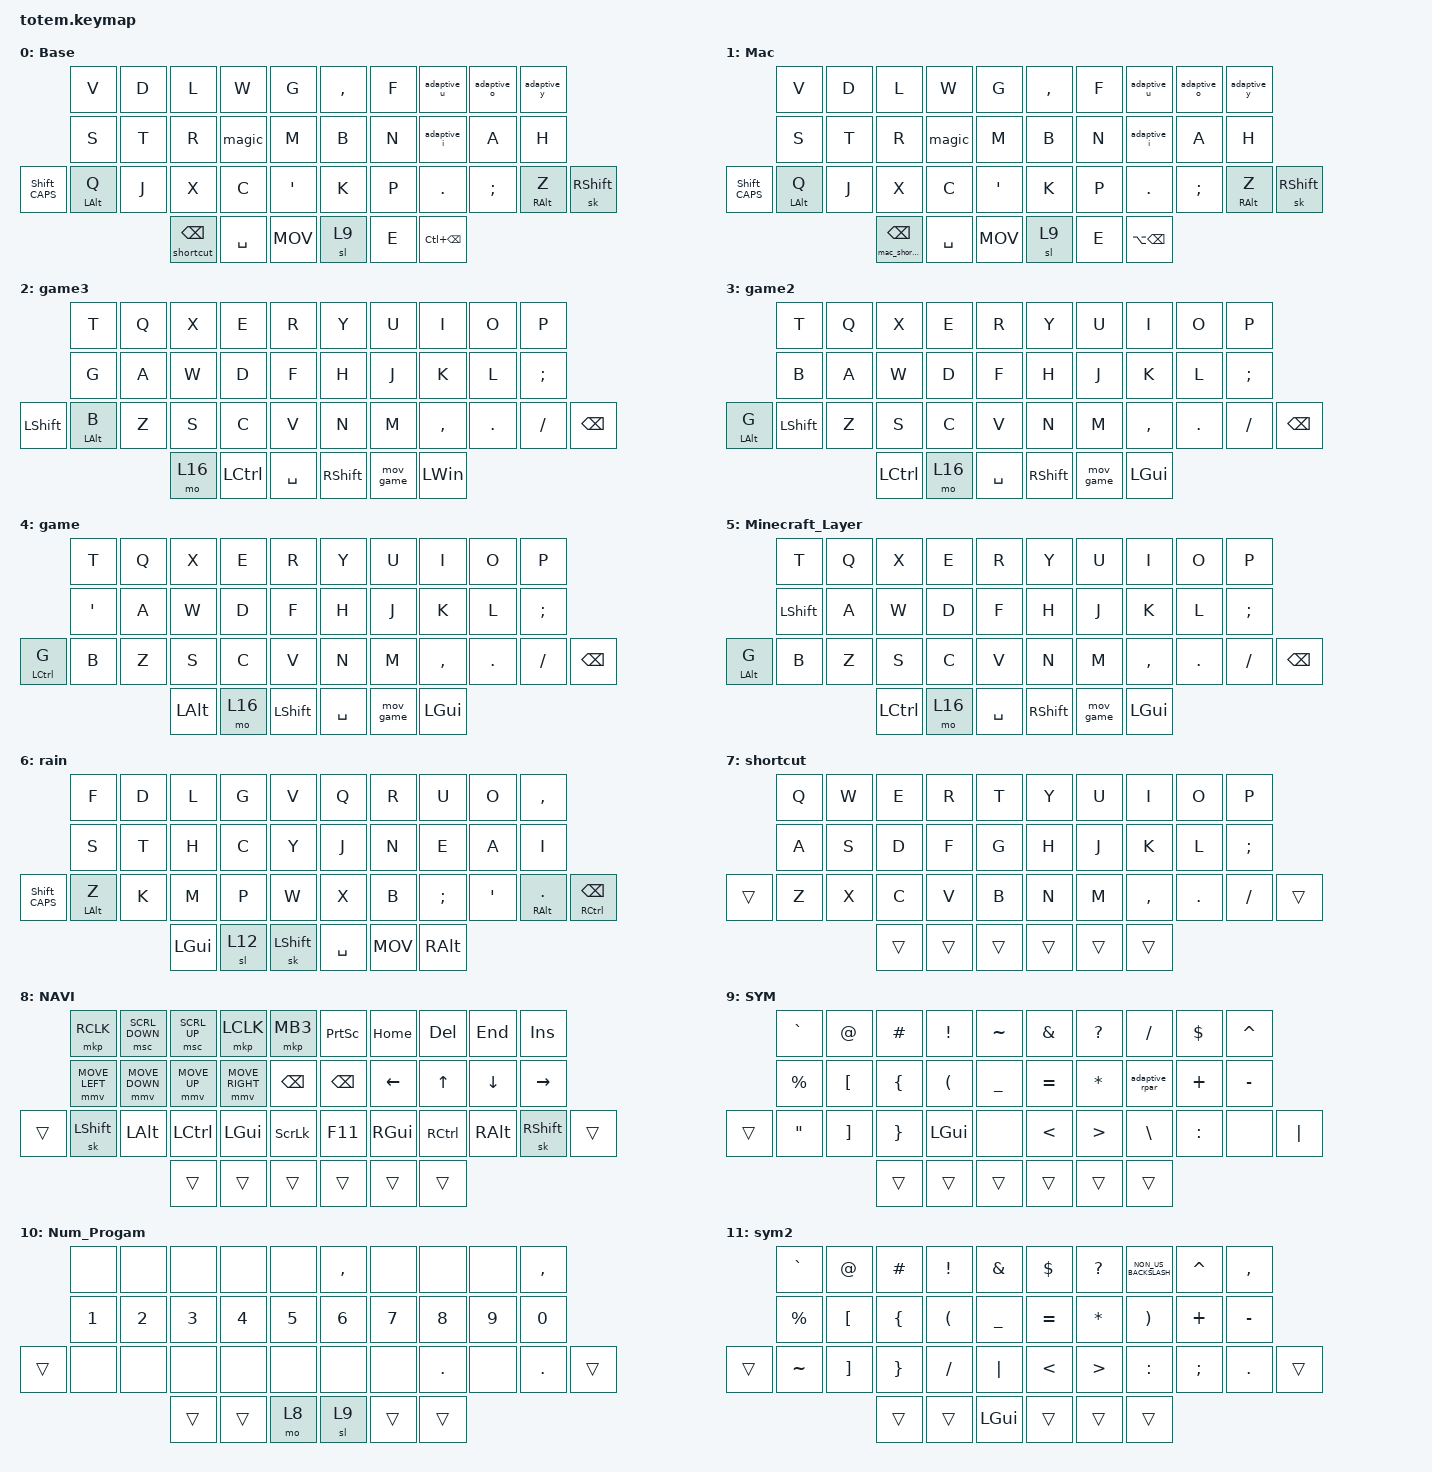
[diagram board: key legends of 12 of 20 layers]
//
//                                                        ▀▀▀▀▀     ▀▀▀▀▀          ▀▀█▀▀
//                                                        ▄▀▀▀▄  ▄  ▄▀▀▀▄  ▄  ▄▀▀▀▄  █  ▄▀▀▀▄
//                                                        █   █  █  █   █  █  █   █  █  █   █
//                                                         ▀▀▀   █   ▀▀▀   █   ▀▀▀   ▀   ▀▀▀
//                                                               █     ▄▄▄█▄▄▄    █   █  
//                                                               ▀     █  █  █     █▄█
//                                                             ▀▀▀▀▀    █  █  █      ▀
//                                                                      ▀  ▀  ▀
//
// ▄▄▄▄▄▄▄▄▄▄▄▄▄▄▄▄▄▄▄▄▄▄▄▄▄▄▄▄▄▄▄▄▄▄▄▄▄▄▄▄▄▄▄▄▄▄▄▄▄▄▄▄▄▄▄▄▄▄▄▄▄▄▄▄▄▄▄▄▄▄▄▄▄▄▄▄▄▄▄▄▄▄▄▄▄▄▄▄▄▄▄▄▄▄▄▄▄▄▄▄▄▄▄▄▄▄▄▄▄▄▄▄▄▄▄▄▄▄▄▄▄▄▄▄▄▄▄▄▄▄▄▄▄▄▄▄▄▄▄▄▄▄▄▄▄▄▄▄▄

#include <behaviors/mouse_keys.dtsi>
#include <dt-bindings/zmk/mouse.h>
#include <behaviors/battery_percentage_printer.dtsi>
#include <behaviors.dtsi>
#include <dt-bindings/zmk/bt.h>
#include <dt-bindings/zmk/keys.h>
#include <dt-bindings/zmk/outputs.h>
#include <dt-bindings/zmk/pointing.h>

#define ZMK_POINTING_DEFAULT_MOVE_VAL 4000 // default: 600
#define ZMK_POINTING_DEFAULT_SCRL_VAL 15    // default: 10
#define BASE 0
#define NAV  1
#define SYM  2
#define ADJ  3

&mt {
    quick-tap-ms = <100>;
    global-quick-tap;
    flavor = "tap-preferred";
    tapping-term-ms = <250>;
};

&sk {
    quick-release;
    release-after-ms = <1500>;
};

&soft_off {
    hold-time-ms = <2000>; // Only turn off it the key is held for 3 seconds or longer.
};

&sl { release-after-ms = <350>; };

/ {
    combos {
        compatible = "zmk,combos";

        esc {
            timeout-ms = <30>;
            key-positions = <2 1>;
            bindings = <&kp ESC>;
            layers = <2 13 8 0 13 3 4 6 1 5>;
        };

        enter {
            bindings = <&kp ENTER>;
            key-positions = <16 17 18>;
            timeout-ms = <30>;
            layers = <2 13 8 0 13 3 4 6 1 5>;
        };

        tab {
            bindings = <&kp TAB>;
            key-positions = <13 12>;
            timeout-ms = <30>;
            layers = <13 8 0 13 6 1>;
        };

        option {
            bindings = <&mo 14>;
            key-positions = <22 23 21>;
            timeout-ms = <30>;
            layers = <2 0 13 3 4 6 1 5>;
        };

        Bluetooth {
            bindings = <&mo 15>;
            key-positions = <2 3 1>;
            timeout-ms = <100>;
            layers = <2 0 3 4 6 1 5>;
        };

        Option_2 {
            bindings = <&mo 14>;
            key-positions = <29 28 30>;
            timeout-ms = <30>;
            layers = <2 0 3 4 6 1 5>;
        };

        Reset_Button {
            bindings = <&kp LC(RA(K))>;
            key-positions = <20 31 35 34>;
            timeout-ms = <50>;
            layers = <2 0 3 4 6 1>;
        };

        tabgaming {
            bindings = <&kp TAB>;
            key-positions = <3 2>;
            timeout-ms = <30>;
            layers = <2 4 3 5>;
        };
    };

    macros {
        macro_ou: macro_ou {
            compatible = "zmk,behavior-macro";
            #binding-cells = <0>;
            wait-ms = <20>;
            tap-ms = <20>;
            bindings = <&kp O &kp U>;
        };

        shortcut: shortcut {
            compatible = "zmk,behavior-macro";
            #binding-cells = <0>;
            bindings =
                <&macro_press>,
                <&kp LCTRL &mo 7>,
                <&macro_pause_for_release>,
                <&macro_release>,
                <&mo 7 &kp LCTRL>;

            label = "SHORTCUT";
        };

        macro_ng: macro_ng {
            compatible = "zmk,behavior-macro";
            #binding-cells = <0>;
            bindings = <&none>;
            label = "MACRO_NG";
        };

        mac_shortcut: mac_shortcut {
            compatible = "zmk,behavior-macro";
            #binding-cells = <0>;
            bindings =
                <&macro_press>,
                <&kp LEFT_ALT &mo 7>,
                <&macro_pause_for_release>,
                <&macro_release>,
                <&mo 7 &kp LEFT_ALT>;

            label = "MAC_SHORTCUT";
        };
    };

    behaviors {
        Shift_CAPS: Shift_CAPS {
            compatible = "zmk,behavior-tap-dance";
            label = "SHIFT_CAPS";
            #binding-cells = <0>;
            bindings = <&sk LEFT_SHIFT>, <&kp CAPSLOCK>;

            tapping-term-ms = <250>;
        };

        Pressy_Layer: Pressy_Layer {
            compatible = "zmk,behavior-tap-dance";
            label = "PRESSY_LAYER";
            #binding-cells = <0>;
            bindings = <&none>, <&none>, <&tog 19>;

            tapping-term-ms = <250>;
        };

        SYM_NUM: SYM_NUM {
            compatible = "zmk,behavior-tap-dance";
            label = "SYM_NUM";
            #binding-cells = <0>;
            bindings = <&sl 7>, <&sl 13>;

            tapping-term-ms = <250>;
        };

        MOV: MOV {
            compatible = "zmk,behavior-tap-dance";
            label = "MOV";
            #binding-cells = <0>;
            bindings = <&mo 8>, <&tog 8>;

            tapping-term-ms = <300>;
        };

        Backspace1: Backspace1 {
            compatible = "zmk,behavior-tap-dance";
            label = "BACKSPACE1";
            #binding-cells = <0>;
            bindings = <&kp BACKSPACE>;
            tapping-term-ms = <450>;
        };

        mov_game: mov_game {
            compatible = "zmk,behavior-tap-dance";
            label = "MOV_GAME";
            #binding-cells = <0>;
            bindings = <&mo 7>, <&mo 8>;

            tapping-term-ms = <300>;
        };

        Backspace_N_Ctrl: Backspace_N_Ctrl {
            compatible = "zmk,behavior-hold-tap";
            label = "BACKSPACE_N_CTRL";
            bindings = <&kp>, <&kp>;

            #binding-cells = <2>;
            tapping-term-ms = <400>;
            flavor = "tap-preferred";
        };

        Left_ALT: Left_ALT {
            compatible = "zmk,behavior-hold-tap";
            label = "LEFT_ALT";
            bindings = <&kp>, <&kp>;

            #binding-cells = <2>;
            flavor = "tap-preferred";
            tapping-term-ms = <400>;
        };

        Right_ALT: Right_ALT {
            compatible = "zmk,behavior-hold-tap";
            label = "RIGHT_ALT";
            bindings = <&kp>, <&kp>;

            #binding-cells = <2>;
            tapping-term-ms = <500>;
            flavor = "tap-preferred";
        };

        new_behavior: new_behavior {
            compatible = "zmk,behavior-hold-tap";
            label = "NEW_BEHAVIOR";
            bindings = <&kp>, <&kp>;

            #binding-cells = <2>;
            flavor = "tap-preferred";
            tapping-term-ms = <500>;
        };

        adaptive_o: adaptive_o {
            compatible = "zmk,behavior-adaptive-key";
            #binding-cells = <0>;

            /* Default output is O */

            bindings = <&kp O>;

            /* If U was pressed right before this, output I instead */

            akt_u {
                trigger-keys = <U>;
                max-prior-idle-ms = <1000>;
                bindings = <&kp I>;
            };
        };

        adaptive_i: adaptive_i {
            compatible = "zmk,behavior-adaptive-key";
            #binding-cells = <0>;

            /* Default output is I */

            bindings = <&kp I>;

            /* If U was pressed right before this, output O instead */

            akt_u {
                trigger-keys = <U>;
                max-prior-idle-ms = <1000>;
                bindings = <&kp O>;
            };
        };

        adaptive_y: adaptive_y {
            compatible = "zmk,behavior-adaptive-key";
            #binding-cells = <0>;

            /* Default output is Y */

            bindings = <&kp Y>;

            /* If E was pressed right before this, output U instead */

            akt_e {
                trigger-keys = <E>;
                max-prior-idle-ms = <1000>;
                bindings = <&kp U>;
            };
        };

        adaptive_u: adaptive_u {
            compatible = "zmk,behavior-adaptive-key";
            #binding-cells = <0>;

            /* Default output is U */

            bindings = <&kp U>;

            /* If E was pressed right before this, output Y instead */

            akt_e {
                trigger-keys = <E>;
                max-prior-idle-ms = <1000>;
                bindings = <&kp Y>;
            };
        };

        adaptive_rpar: adaptive_rpar {
            compatible = "zmk,behavior-adaptive-key";
            #binding-cells = <0>;

            /* Output default adalah ')' */

            bindings = <&kp RPAR>;

            /* Kalau sebelum tombol ini dipencet '>' (GT), ubah output ')' jadi '=' (hasil akhir: '>=') */

            akt_gt {
                trigger-keys = <GT>;
                max-prior-idle-ms = <1000>;
                bindings = <&kp EQUAL>;
            };

            /* Kalau sebelum tombol ini dipencet '<' (LT), ubah output ')' jadi '=' (hasil akhir: '<=') */

            akt_lt {
                trigger-keys = <LT>;
                max-prior-idle-ms = <1000>;
                bindings = <&kp EQUAL>;
            };

            /* Kalau sebelum tombol ini dipencet '=' (EQUAL), ubah output ')' jadi '>' (hasil akhir: '=>') */

            akt_eq {
                trigger-keys = <EQUAL>;
                max-prior-idle-ms = <1000>;
                bindings = <&kp GREATER_THAN>;
            };
        };

        magic: magic_key {
            compatible = "zmk,behavior-adaptive-key";
            #binding-cells = <0>;
            bindings = <&key_repeat>;

            /* Default output if no trigger matches (Repeat Key) */

            akt_bu {
                trigger-keys = <B>;
                max-prior-idle-ms = <1000>;
                bindings = <&kp U>;
            };

            akt_hy {
                trigger-keys = <H>;
                max-prior-idle-ms = <1000>;
                bindings = <&kp Y>;
            };

            akt_rl {
                trigger-keys = <R>;
                max-prior-idle-ms = <1000>;
                bindings = <&kp L>;
            };

            akt_yDOT {
                trigger-keys = <Y>;
                max-prior-idle-ms = <1000>;
                bindings = <&kp DOT>;
            };

            akt_ay {
                trigger-keys = <A>;
                max-prior-idle-ms = <1000>;
                bindings = <&kp Y>;
            };

            akt_kn {
                trigger-keys = <K>;
                max-prior-idle-ms = <1000>;
                bindings = <&kp N>;
            };

            akt_nk {
                trigger-keys = <N>;
                max-prior-idle-ms = <1000>;
                bindings = <&kp K>;
            };
        };

        Backspace_Shortuct: Backspace_Shortuct {
            compatible = "zmk,behavior-hold-tap";
            label = "BACKSPACE_SHORTUCT";
            bindings = <&shortcut>, <&kp>;

            #binding-cells = <2>;
            tapping-term-ms = <400>;
            quick-tap-ms = <175>;
            require-prior-idle-ms = <125>;
            flavor = "balanced";
            retro-tap;
        };

        SL6_Windows: SL6_Windows {
            compatible = "zmk,behavior-tap-dance";
            label = "SL6_WINDOWS";
            #binding-cells = <0>;
            bindings = <&sl 7>, <&kp LGUI>;

            tapping-term-ms = <150>;
        };

        MAC_Backspace_Shortcut: MAC_Backspace_Shortcut {
            compatible = "zmk,behavior-hold-tap";
            label = "MAC_BACKSPACE_SHORTCUT";
            bindings = <&mac_shortcut>, <&kp>;

            #binding-cells = <2>;
            flavor = "balanced";
            tapping-term-ms = <400>;
            quick-tap-ms = <175>;
            require-prior-idle-ms = <125>;
            retro-tap;
        };
    };

    keymap {
        compatible = "zmk,keymap";

        // ▄▄▄▄▄▄▄▄▄▄▄▄▄▄▄▄▄▄▄▄▄▄▄▄▄▄▄▄▄▄▄▄▄▄▄▄▄▄▄▄▄▄▄▄▄▄▄▄▄▄▄▄▄▄▄▄▄▄▄▄▄▄▄▄▄▄▄▄▄▄▄▄▄▄▄▄▄▄▄▄▄▄▄▄▄▄▄▄▄▄▄▄▄▄▄▄▄▄▄▄▄▄▄▄▄▄▄▄▄▄▄▄▄▄▄▄▄▄▄▄▄▄▄▄▄▄▄▄▄▄▄▄▄▄▄▄▄▄▄▄▄▄▄▄▄▄▄▄▄

        sunstone_code {
            label = "Base";
            bindings = <
             &kp V                 &kp D  &kp L                            &kp W      &kp G      &kp COMMA  &kp F  &adaptive_u        &adaptive_o  &adaptive_y
             &kp S                 &kp T  &kp R                            &magic     &kp M      &kp B      &kp N  &adaptive_i        &kp A        &kp H
&Shift_CAPS  &Left_ALT LEFT_ALT Q  &kp J  &kp X                            &kp C      &kp SQT    &kp K      &kp P  &kp DOT            &kp SEMI     &Right_ALT RIGHT_ALT Z  &sk RIGHT_SHIFT
                                          &Backspace_Shortuct 0 BACKSPACE  &kp SPACE  &MOV       &sl 9      &kp E  &kp LC(BACKSPACE)
            >;
        };

        BaseMac {
            label = "Mac";
            bindings = <
             &kp V                 &kp D  &kp L                                &kp W      &kp G      &kp COMMA  &kp F  &adaptive_u        &adaptive_o  &adaptive_y
             &kp S                 &kp T  &kp R                                &magic     &kp M      &kp B      &kp N  &adaptive_i        &kp A        &kp H
&Shift_CAPS  &Left_ALT LEFT_ALT Q  &kp J  &kp X                                &kp C      &kp SQT    &kp K      &kp P  &kp DOT            &kp SEMI     &Right_ALT RIGHT_ALT Z  &sk RIGHT_SHIFT
                                          &MAC_Backspace_Shortcut 0 BACKSPACE  &kp SPACE  &MOV       &sl 9      &kp E  &kp LA(BACKSPACE)
            >;
        };

        Gaming_Volley {
            label = "game3";
            bindings = <
                &kp T           &kp Q  &kp X   &kp E             &kp R        &kp Y            &kp U      &kp I         &kp O    &kp P
                &kp G           &kp A  &kp W   &kp D             &kp F        &kp H            &kp J      &kp K         &kp L    &kp SEMI
&kp LEFT_SHIFT  &mt LEFT_ALT B  &kp Z  &kp S   &kp C             &kp V        &kp N            &kp M      &kp COMMA     &kp DOT  &kp FSLH  &kp BACKSPACE
                                       &mo 16  &kp LEFT_CONTROL  &kp SPACE    &kp RIGHT_SHIFT  &mov_game  &kp LEFT_WIN
            >;
        };

        Gaming2 {
            label = "game2";
            bindings = <
                &kp T           &kp Q  &kp X      &kp E   &kp R        &kp Y            &kp U      &kp I         &kp O    &kp P
                &kp B           &kp A  &kp W      &kp D   &kp F        &kp H            &kp J      &kp K         &kp L    &kp SEMI
&mt LEFT_ALT G  &kp LEFT_SHIFT  &kp Z  &kp S      &kp C   &kp V        &kp N            &kp M      &kp COMMA     &kp DOT  &kp FSLH  &kp BACKSPACE
                                       &kp LCTRL  &mo 16  &kp SPACE    &kp RIGHT_SHIFT  &mov_game  &kp LEFT_GUI
            >;
        };

        Gaming {
            label = "game";
            bindings = <
                    &kp T     &kp Q  &kp X         &kp E   &kp R             &kp Y      &kp U      &kp I         &kp O    &kp P
                    &kp APOS  &kp A  &kp W         &kp D   &kp F             &kp H      &kp J      &kp K         &kp L    &kp SEMI
&mt LEFT_CONTROL G  &kp B     &kp Z  &kp S         &kp C   &kp V             &kp N      &kp M      &kp COMMA     &kp DOT  &kp FSLH  &kp BACKSPACE
                                     &kp LEFT_ALT  &mo 16  &kp LEFT_SHIFT    &kp SPACE  &mov_game  &kp LEFT_GUI
            >;
        };

        Minecraft {
            label = "Minecraft_Layer";
            bindings = <
                &kp T      &kp Q  &kp X      &kp E   &kp R        &kp Y            &kp U      &kp I         &kp O    &kp P
                &kp LSHFT  &kp A  &kp W      &kp D   &kp F        &kp H            &kp J      &kp K         &kp L    &kp SEMI
&mt LEFT_ALT G  &kp B      &kp Z  &kp S      &kp C   &kp V        &kp N            &kp M      &kp COMMA     &kp DOT  &kp FSLH  &kp BACKSPACE
                                  &kp LCTRL  &mo 16  &kp SPACE    &kp RIGHT_SHIFT  &mov_game  &kp LEFT_GUI
            >;
        };

        rain {
            label = "rain";
            bindings = <
             &kp F                 &kp D  &kp L         &kp G   &kp V             &kp Q      &kp R  &kp U          &kp O    &kp COMMA
             &kp S                 &kp T  &kp H         &kp C   &kp Y             &kp J      &kp N  &kp E          &kp A    &kp I
&Shift_CAPS  &Left_ALT LEFT_ALT Z  &kp K  &kp M         &kp P   &kp W             &kp X      &kp B  &kp SEMI       &kp SQT  &Right_ALT RIGHT_ALT PERIOD  &Backspace_N_Ctrl RIGHT_CONTROL BACKSPACE
                                          &kp LEFT_GUI  &sl 12  &sk LEFT_SHIFT    &kp SPACE  &MOV   &kp RIGHT_ALT
            >;
        };

        shortcut {
            bindings = <
        &kp Q  &kp W  &kp E   &kp R   &kp T     &kp Y   &kp U   &kp I      &kp O    &kp P
        &kp A  &kp S  &kp D   &kp F   &kp G     &kp H   &kp J   &kp K      &kp L    &kp SEMI
&trans  &kp Z  &kp X  &kp C   &kp V   &kp B     &kp N   &kp M   &kp COMMA  &kp DOT  &kp FSLH  &trans
                      &trans  &trans  &trans    &trans  &trans  &trans
            >;
        };

        Movement {
            label = "NAVI";
            bindings = <
        &mkp RCLK       &msc SCRL_DOWN  &msc SCRL_UP  &mkp LCLK        &mkp MB3          &kp PRINTSCREEN  &kp HOME        &kp DEL       &kp END        &kp INSERT
        &mmv MOVE_LEFT  &mmv MOVE_DOWN  &mmv MOVE_UP  &mmv MOVE_RIGHT  &kp BSPC          &kp BSPC         &kp LEFT_ARROW  &kp UP_ARROW  &kp DOWN       &kp RIGHT
&trans  &sk LEFT_SHIFT  &kp LEFT_ALT    &kp LCTRL     &kp LGUI         &kp SCROLLLOCK    &kp F11          &kp RGUI        &kp RCTRL     &kp RIGHT_ALT  &sk RIGHT_SHIFT  &trans
                                        &trans        &trans           &trans            &trans           &trans          &trans
            >;
        };

        Special_Characters {
            label = "SYM";
            bindings = <
        &kp GRAVE          &kp AT_SIGN        &kp HASH         &kp EXCLAMATION       &kp TILDE         &kp AMPERSAND  &kp QUESTION      &kp FSLH        &kp DOLLAR  &kp CARET
        &kp PERCENT        &kp LEFT_BRACKET   &kp LEFT_BRACE   &kp LEFT_PARENTHESIS  &kp UNDERSCORE    &kp EQUAL      &kp ASTERISK      &adaptive_rpar  &kp PLUS    &kp MINUS
&trans  &kp DOUBLE_QUOTES  &kp RIGHT_BRACKET  &kp RIGHT_BRACE  &kp LGUI              &none             &kp LESS_THAN  &kp GREATER_THAN  &kp BSLH        &kp COLON   &none      &kp PIPE
                                              &trans           &trans                &trans            &trans         &trans            &trans
            >;
        };

        Num_Progam {
            bindings = <
        &none   &none   &none   &none   &none     &kp COMMA  &none   &none       &none   &kp COMMA
        &kp N1  &kp N2  &kp N3  &kp N4  &kp N5    &kp N6     &kp N7  &kp N8      &kp N9  &kp N0
&trans  &none   &none   &none   &none   &none     &none      &none   &kp PERIOD  &none   &kp PERIOD  &trans
                        &trans  &trans  &mo 8     &sl 9      &trans  &trans
            >;
        };

        sym2 {
            label = "sym2";
            bindings = <
        &kp GRAVE    &kp AT_SIGN        &kp HASH         &kp EXCLAMATION       &kp AMPERSAND     &kp DOLLAR     &kp QUESTION      &kp NON_US_BACKSLASH   &kp CARET  &kp COMMA
        &kp PERCENT  &kp LEFT_BRACKET   &kp LEFT_BRACE   &kp LEFT_PARENTHESIS  &kp UNDERSCORE    &kp EQUAL      &kp ASTERISK      &kp RIGHT_PARENTHESIS  &kp PLUS   &kp MINUS
&trans  &kp TILDE    &kp RIGHT_BRACKET  &kp RIGHT_BRACE  &kp SLASH             &kp PIPE          &kp LESS_THAN  &kp GREATER_THAN  &kp COLON              &kp SEMI   &kp DOT    &trans
                                        &trans           &trans                &kp LGUI          &trans         &trans            &trans
            >;
        };

        mov {
            label = "mov";
            bindings = <
        &mkp RCLK       &msc SCRL_DOWN  &msc SCRL_UP  &kp SLCK         &mkp MB3     &kp PRINTSCREEN  &kp HOME        &kp DEL       &kp END   &kp INSERT
        &mmv MOVE_LEFT  &mmv MOVE_DOWN  &mmv MOVE_UP  &mmv MOVE_RIGHT  &mkp LCLK    &kp F11          &kp LEFT_ARROW  &kp UP_ARROW  &kp DOWN  &kp RIGHT
&trans  &kp F1          &kp F2          &kp F3        &kp F4           &kp F5       &kp F6           &kp F7          &kp F8        &kp F9    &kp F10     &trans
                                        &trans        &trans           &trans       &trans           &trans          &trans
            >;
        };

        NUM {
            bindings = <
        &none   &none   &none   &none     &none     &none   &none   &none   &none   &none
        &kp N7  &kp N5  &kp N3  &kp N1    &kp N9    &kp N0  &kp N2  &kp N4  &kp N6  &kp N8
&trans  &none   &none   &none   &none     &none     &none   &none   &none   &none   &none   &trans
                        &trans  &SYM_NUM  &trans    &trans  &MOV    &trans
            >;
        };

        Option {
            label = "OPT";
            bindings = <
         &tog 5       &tog 4       &tog 3          &tog 2             &tog 0                  &tog 0         &tog 2             &tog 3        &tog 4       &tog 5
         &tog 6       &none        &bapp           &kp C_VOLUME_UP    &kp C_BRIGHTNESS_INC    &kp C_BRI_UP   &kp C_VOLUME_UP    &bapp         &none        &tog 6
&tog 19  &kp C_POWER  &kp C_SLEEP  &tog 1          &kp C_VOLUME_DOWN  &kp C_BRIGHTNESS_DEC    &kp C_BRI_DEC  &kp C_VOLUME_DOWN  &tog 1        &kp C_SLEEP  &kp C_POWER  &tog 19
                                   &kp C_PREVIOUS  &kp C_PLAY_PAUSE   &kp C_NEXT              &out OUT_USB   &kp C_MUTE         &out OUT_USB
            >;
        };

        Bluetooth {
            bindings = <
        &trans  &trans  &trans  &trans  &trans    &none          &bt BT_PRV     &bt BT_CLR     &bt BT_CLR_ALL  &bt BT_NXT
        &trans  &trans  &trans  &trans  &trans    &bt BT_SEL 0   &bt BT_SEL 1   &bt BT_SEL 2   &bt BT_SEL 3    &bt BT_SEL 4
&trans  &trans  &trans  &trans  &trans  &trans    &bt BT_DISC 0  &bt BT_DISC 1  &bt BT_DISC 2  &bt BT_DISC 3   &bt BT_DISC 4  &trans
                        &trans  &trans  &trans    &trans         &trans         &trans
            >;
        };

        Num_Gaming {
            bindings = <
        &kp N1  &kp N2  &kp N3  &kp N4  &kp N5    &none   &none   &none   &none  &none
        &none   &none   &none   &none   &none     &none   &none   &none   &none  &none
&trans  &kp N6  &kp N7  &kp N8  &kp N9  &kp N0    &none   &none   &none   &none  &none  &trans
                        &trans  &trans  &trans    &trans  &trans  &trans
            >;
        };

        mov2 {
            label = "mov2";
            bindings = <
        &mkp RCLK       &msc SCRL_DOWN  &msc SCRL_UP  &kp SLCK         &mkp MB3     &kp PRINTSCREEN  &kp HOME        &kp DEL       &kp END   &kp INSERT
        &mmv MOVE_LEFT  &mmv MOVE_DOWN  &mmv MOVE_UP  &mmv MOVE_RIGHT  &mkp LCLK    &kp F11          &kp LEFT_ARROW  &kp UP_ARROW  &kp DOWN  &kp RIGHT
&trans  &kp F1          &kp F2          &kp F3        &kp F4           &kp F5       &kp F6           &kp F7          &kp F8        &kp F9    &kp F10     &trans
                                        &trans        &trans           &trans       &trans           &trans          &trans
            >;
        };

        Number {
            bindings = <
        &none  &none  &none   &none   &none     &none   &kp N7  &kp N8  &kp N9  &none
        &none  &none  &none   &none   &none     &none   &kp N4  &kp N5  &kp N6  &none
&trans  &none  &none  &none   &none   &none     &none   &kp N1  &kp N2  &kp N3  &none  &trans
                      &trans  &trans  &trans    &trans  &kp N0  &trans
            >;
        };

        None_Layer {
            bindings = <
       &none  &none  &none          &none  &none    &none  &none  &none  &none  &none
       &none  &none  &none          &none  &none    &none  &none  &none  &none  &none
&none  &none  &none  &none          &none  &none    &none  &none  &none  &none  &none  &none
                     &Pressy_Layer  &none  &none    &none  &none  &none
            >;
        };
    };

    conditional_layers {
        compatible = "zmk,conditional-layers";

        num {
            if-layers = <8 9>;
            then-layer = <10>;
        };

        num2 {
            if-layers = <8 9>;
            then-layer = <10>;
        };

        mov_game {
            if-layers = <16 9>;
            then-layer = <17>;
        };

        move2_game {
            if-layers = <16 9>;
            then-layer = <17>;
        };
    };
};
